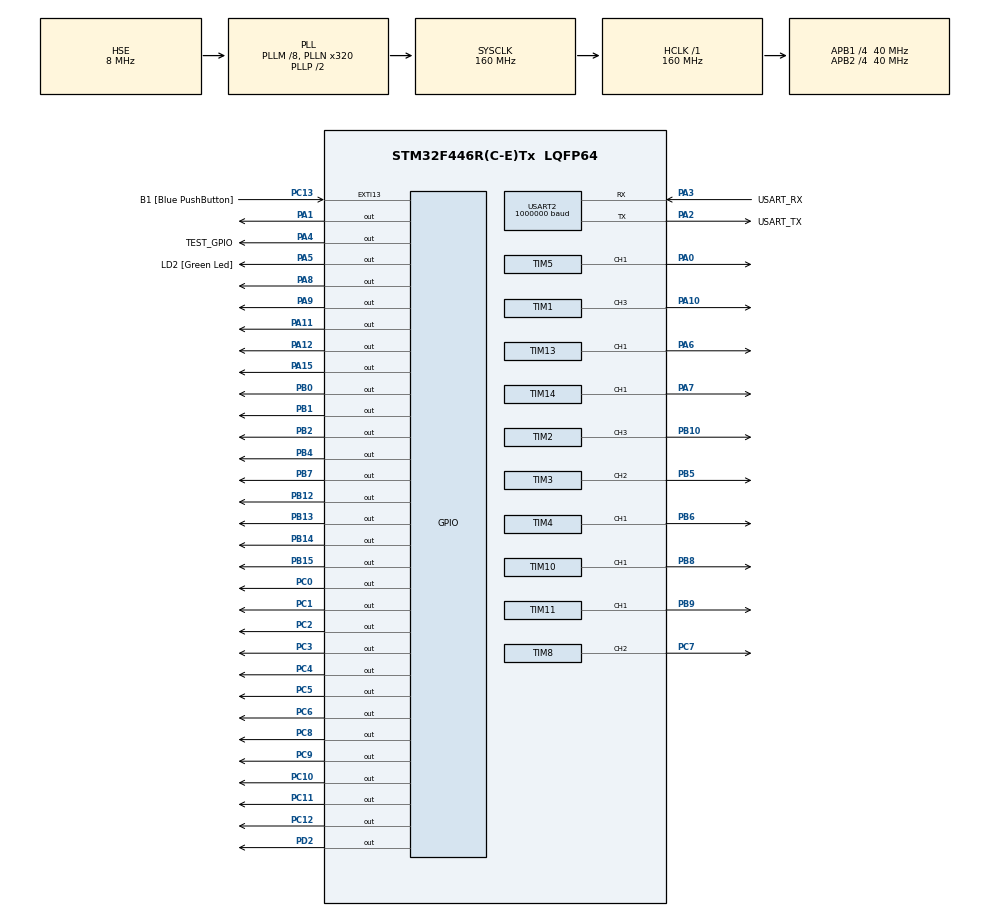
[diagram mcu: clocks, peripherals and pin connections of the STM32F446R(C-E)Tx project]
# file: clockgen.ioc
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Mcu.Family=STM32F4
Mcu.Name=STM32F446R(C-E)Tx
Mcu.Package=LQFP64
Mcu.UserConstants=TIM_TICK_FREQ,1000000;TIM_CLOCK_FREQ,80000000;SYS_CLOCK_FREQ,160000000
NVIC.PriorityGroup=NVIC_PRIORITYGROUP_2
NVIC.TIM6_DAC_IRQn=true\:0\:0\:true\:true\:true\:2\:true\:false
NVIC.USART2_IRQn=true\:0\:0\:true\:true\:true\:1\:true\:false
PA0-WKUP.GPIO_Speed=GPIO_SPEED_FREQ_VERY_HIGH
PA0-WKUP.Signal=S_TIM5_CH1
PA1.GPIO_Speed=GPIO_SPEED_FREQ_VERY_HIGH
PA1.Signal=GPIO_Output
PA10.GPIO_Speed=GPIO_SPEED_FREQ_VERY_HIGH
PA10.Signal=S_TIM1_CH3
PA11.GPIO_Speed=GPIO_SPEED_FREQ_VERY_HIGH
PA11.Signal=GPIO_Output
PA12.GPIO_Speed=GPIO_SPEED_FREQ_VERY_HIGH
PA12.Signal=GPIO_Output
PA13.GPIO_Label=TMS
PA13.Mode=Serial_Wire
PA13.Signal=SYS_JTMS-SWDIO
PA14.GPIO_Label=TCK
PA14.Mode=Serial_Wire
PA14.Signal=SYS_JTCK-SWCLK
PA15.GPIO_Speed=GPIO_SPEED_FREQ_VERY_HIGH
PA15.Signal=GPIO_Output
PA2.GPIO_Label=USART_TX
PA2.Mode=Asynchronous
PA2.Signal=USART2_TX
PA3.GPIO_Label=USART_RX
PA3.Mode=Asynchronous
PA3.Signal=USART2_RX
PA4.GPIO_Label=TEST_GPIO
PA4.GPIO_Speed=GPIO_SPEED_FREQ_VERY_HIGH
PA4.Signal=GPIO_Output
PA5.GPIO_Label=LD2 [Green Led]
PA5.Signal=GPIO_Output
PA6.GPIO_Speed=GPIO_SPEED_FREQ_VERY_HIGH
PA6.Signal=S_TIM13_CH1
PA7.GPIO_Speed=GPIO_SPEED_FREQ_VERY_HIGH
PA7.Signal=S_TIM14_CH1
PA8.GPIO_Speed=GPIO_SPEED_FREQ_VERY_HIGH
PA8.Signal=GPIO_Output
PA9.GPIO_Speed=GPIO_SPEED_FREQ_VERY_HIGH
PA9.Signal=GPIO_Output
PB0.GPIO_Speed=GPIO_SPEED_FREQ_VERY_HIGH
PB0.Signal=GPIO_Output
PB1.GPIO_Speed=GPIO_SPEED_FREQ_VERY_HIGH
PB1.Signal=GPIO_Output
PB10.GPIO_Speed=GPIO_SPEED_FREQ_VERY_HIGH
PB10.Signal=S_TIM2_CH3
PB12.GPIO_Speed=GPIO_SPEED_FREQ_VERY_HIGH
PB12.Signal=GPIO_Output
PB13.GPIO_Speed=GPIO_SPEED_FREQ_VERY_HIGH
PB13.Signal=GPIO_Output
PB14.GPIO_Speed=GPIO_SPEED_FREQ_VERY_HIGH
PB14.Signal=GPIO_Output
PB15.GPIO_Speed=GPIO_SPEED_FREQ_VERY_HIGH
PB15.Signal=GPIO_Output
PB2.GPIO_Speed=GPIO_SPEED_FREQ_VERY_HIGH
PB2.Signal=GPIO_Output
PB3.GPIO_Label=SWO
PB3.Signal=SYS_JTDO-SWO
PB4.GPIO_Speed=GPIO_SPEED_FREQ_VERY_HIGH
PB4.Signal=GPIO_Output
PB5.GPIO_Speed=GPIO_SPEED_FREQ_VERY_HIGH
PB5.Signal=S_TIM3_CH2
PB6.GPIO_Speed=GPIO_SPEED_FREQ_VERY_HIGH
PB6.Signal=S_TIM4_CH1
PB7.GPIO_Speed=GPIO_SPEED_FREQ_VERY_HIGH
PB7.Signal=GPIO_Output
PB8.GPIO_Speed=GPIO_SPEED_FREQ_VERY_HIGH
PB8.Signal=S_TIM10_CH1
PB9.GPIO_Speed=GPIO_SPEED_FREQ_VERY_HIGH
PB9.Signal=S_TIM11_CH1
PC0.GPIO_ModeDefaultOutputPP=GPIO_MODE_OUTPUT_PP
PC0.GPIO_PuPd=GPIO_NOPULL
PC0.GPIO_Speed=GPIO_SPEED_FREQ_VERY_HIGH
PC0.Signal=GPIO_Output
PC1.GPIO_ModeDefaultOutputPP=GPIO_MODE_OUTPUT_PP
PC1.GPIO_PuPd=GPIO_NOPULL
PC1.GPIO_Speed=GPIO_SPEED_FREQ_VERY_HIGH
PC1.Signal=GPIO_Output
PC10.GPIO_Speed=GPIO_SPEED_FREQ_VERY_HIGH
PC10.Signal=GPIO_Output
PC11.GPIO_Speed=GPIO_SPEED_FREQ_VERY_HIGH
PC11.Signal=GPIO_Output
PC12.GPIO_Speed=GPIO_SPEED_FREQ_VERY_HIGH
PC12.Signal=GPIO_Output
PC13.GPIO_Label=B1 [Blue PushButton]
PC13.GPIO_ModeDefaultEXTI=GPIO_MODE_IT_FALLING
PC13.Signal=GPXTI13
PC14-OSC32_IN.Mode=LSE-External-Oscillator
PC14-OSC32_IN.Signal=RCC_OSC32_IN
PC15-OSC32_OUT.Mode=LSE-External-Oscillator
PC15-OSC32_OUT.Signal=RCC_OSC32_OUT
PC2.GPIO_ModeDefaultOutputPP=GPIO_MODE_OUTPUT_PP
PC2.GPIO_PuPd=GPIO_NOPULL
PC2.GPIO_Speed=GPIO_SPEED_FREQ_VERY_HIGH
PC2.Signal=GPIO_Output
PC3.GPIO_ModeDefaultOutputPP=GPIO_MODE_OUTPUT_PP
PC3.GPIO_PuPd=GPIO_NOPULL
PC3.GPIO_Speed=GPIO_SPEED_FREQ_VERY_HIGH
PC3.Signal=GPIO_Output
PC4.GPIO_Speed=GPIO_SPEED_FREQ_VERY_HIGH
PC4.Signal=GPIO_Output
PC5.GPIO_Speed=GPIO_SPEED_FREQ_VERY_HIGH
PC5.Signal=GPIO_Output
PC6.GPIO_Speed=GPIO_SPEED_FREQ_VERY_HIGH
PC6.Signal=GPIO_Output
PC7.GPIO_Speed=GPIO_SPEED_FREQ_VERY_HIGH
PC7.Signal=S_TIM8_CH2
PC8.GPIO_Speed=GPIO_SPEED_FREQ_VERY_HIGH
PC8.Signal=GPIO_Output
PC9.GPIO_Speed=GPIO_SPEED_FREQ_VERY_HIGH
PC9.Signal=GPIO_Output
PD2.GPIO_Speed=GPIO_SPEED_FREQ_VERY_HIGH
PD2.Signal=GPIO_Output
PH0-OSC_IN.Mode=HSE-External-Oscillator
PH0-OSC_IN.Signal=RCC_OSC_IN
PH1-OSC_OUT.Mode=HSE-External-Oscillator
PH1-OSC_OUT.Signal=RCC_OSC_OUT
ProjectManager.HeapSize=0x200
ProjectManager.StackSize=0x400
ProjectManager.TargetToolchain=STM32CubeIDE
RCC.48MHZClocksFreq_Value=84000000
RCC.AHBFreq_Value=160000000
RCC.APB1CLKDivider=RCC_HCLK_DIV4
RCC.APB1Freq_Value=40000000
RCC.APB1TimFreq_Value=80000000
RCC.APB2CLKDivider=RCC_HCLK_DIV4
RCC.APB2Freq_Value=40000000
RCC.APB2TimFreq_Value=80000000
RCC.CortexFreq_Value=160000000
RCC.FLatency-AdvancedSettings=FLASH_LATENCY_5
RCC.HCLKFreq_Value=160000000
RCC.HSE_VALUE=8000000
RCC.HSI_VALUE=16000000
RCC.PLLM=8
RCC.PLLN=320
RCC.PLLSourceVirtual=RCC_PLLSOURCE_HSE
RCC.SYSCLKFreq_VALUE=160000000
RCC.SYSCLKSource=RCC_SYSCLKSOURCE_PLLCLK
RCC.USBFreq_Value=160000000
RCC.VCOOutputFreq_Value=320000000
SH.S_TIM10_CH1.0=TIM10_CH1,Output Compare1 CH1
SH.S_TIM11_CH1.0=TIM11_CH1,Output Compare1 CH1
SH.S_TIM13_CH1.0=TIM13_CH1,Output Compare1 CH1
SH.S_TIM14_CH1.0=TIM14_CH1,Output Compare1 CH1
SH.S_TIM1_CH3.0=TIM1_CH3,Output Compare3 CH3
SH.S_TIM2_CH3.0=TIM2_CH3,Output Compare3 CH3
SH.S_TIM3_CH2.0=TIM3_CH2,Output Compare2 CH2
SH.S_TIM4_CH1.0=TIM4_CH1,Output Compare1 CH1
SH.S_TIM5_CH1.0=TIM5_CH1,Output Compare1 CH1
SH.S_TIM8_CH2.0=TIM8_CH2,Output Compare2 CH2
TIM1.AutoReloadPreload=TIM_AUTORELOAD_PRELOAD_DISABLE
TIM1.AutomaticOutput=TIM_AUTOMATICOUTPUT_ENABLE
TIM1.BreakState=TIM_BREAK_DISABLE
TIM1.Channel-Output\ Compare3\ CH3=TIM_CHANNEL_3
TIM1.OC3Preload=ENABLE
TIM1.OCIdleState_3=TIM_OCIDLESTATE_RESET
TIM1.OCMode_3=TIM_OCMODE_TOGGLE
TIM1.OCPolarity_3=TIM_OCPOLARITY_LOW
TIM1.OffStateIDLEMode=TIM_OSSI_ENABLE
TIM1.OffStateRunMode=TIM_OSSR_ENABLE
TIM1.Pulse-Output\ Compare3\ CH3=0
TIM1.TIM_MasterOutputTrigger=TIM_TRGO_ENABLE
TIM1.TIM_MasterSlaveMode=TIM_MASTERSLAVEMODE_ENABLE
TIM10.Channel=TIM_CHANNEL_1
TIM10.OCMode_1=TIM_OCMODE_TOGGLE
TIM11.Channel=TIM_CHANNEL_1
TIM11.OCMode_1=TIM_OCMODE_TOGGLE
TIM13.Channel=TIM_CHANNEL_1
TIM13.OCMode_1=TIM_OCMODE_TOGGLE
TIM14.Channel=TIM_CHANNEL_1
TIM14.OCMode_1=TIM_OCMODE_TOGGLE
TIM2.AutoReloadPreload=TIM_AUTORELOAD_PRELOAD_DISABLE
TIM2.Channel-Output\ Compare3\ CH3=TIM_CHANNEL_3
TIM2.OC3Preload=ENABLE
TIM2.OCMode_3=TIM_OCMODE_TOGGLE
TIM2.TIM_MasterOutputTrigger=TIM_TRGO_ENABLE
TIM2.TIM_MasterSlaveMode=TIM_MASTERSLAVEMODE_ENABLE
TIM3.Channel-Output\ Compare2\ CH2=TIM_CHANNEL_2
TIM3.OCMode_2=TIM_OCMODE_TOGGLE
TIM3.Period=6553
TIM4.Channel-Output\ Compare1\ CH1=TIM_CHANNEL_1
TIM4.OCMode_1=TIM_OCMODE_TOGGLE
TIM5.Channel-Output\ Compare1\ CH1=TIM_CHANNEL_1
TIM5.OCMode_1=TIM_OCMODE_TOGGLE
TIM6.Period=(TIM_CLOCK_FREQ/TIM_TICK_FREQ) - 1
TIM8.AutomaticOutput=TIM_AUTOMATICOUTPUT_ENABLE
TIM8.Channel-Output\ Compare2\ CH2=TIM_CHANNEL_2
TIM8.OCMode_2=TIM_OCMODE_TOGGLE
TIM8.OCPolarity_2=TIM_OCPOLARITY_LOW
TIM8.OffStateIDLEMode=TIM_OSSI_ENABLE
TIM8.OffStateRunMode=TIM_OSSR_ENABLE
TIM8.Period=8000
USART2.BaudRate=1000000
USART2.VirtualMode=VM_ASYNC
VP_CRC_VS_CRC.Mode=CRC_Activate
VP_TIM10_VS_ClockSourceINT.Mode=Enable_Timer
VP_TIM11_VS_ClockSourceINT.Mode=Enable_Timer
VP_TIM12_VS_ClockSourceINT.Mode=Internal
VP_TIM13_VS_ClockSourceINT.Mode=Enable_Timer
VP_TIM14_VS_ClockSourceINT.Mode=Enable_Timer
VP_TIM1_VS_ClockSourceINT.Mode=Internal
VP_TIM1_VS_ClockSourceITR.Mode=TriggerSource_ITR0
VP_TIM2_VS_ClockSourceINT.Mode=Internal
VP_TIM2_VS_ClockSourceITR.Mode=TriggerSource_ITR0
VP_TIM2_VS_ControllerModeTrigger.Mode=Trigger Mode
VP_TIM3_VS_ClockSourceINT.Mode=Internal
VP_TIM3_VS_ClockSourceITR.Mode=TriggerSource_ITR0
VP_TIM3_VS_ControllerModeTrigger.Mode=Trigger Mode
VP_TIM4_VS_ClockSourceINT.Mode=Internal
VP_TIM4_VS_ClockSourceITR.Mode=TriggerSource_ITR0
VP_TIM4_VS_ControllerModeTrigger.Mode=Trigger Mode
VP_TIM5_VS_ClockSourceINT.Mode=Internal
VP_TIM5_VS_ClockSourceITR.Mode=TriggerSource_ITR0
VP_TIM5_VS_ControllerModeTrigger.Mode=Trigger Mode
VP_TIM6_VS_ClockSourceINT.Mode=Enable_Timer
VP_TIM8_VS_ClockSourceINT.Mode=Internal
VP_TIM8_VS_ClockSourceITR.Mode=TriggerSource_ITR0
VP_TIM8_VS_ControllerModeTrigger.Mode=Trigger Mode
board=NUCLEO-F446RE

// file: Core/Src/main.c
/* USER CODE BEGIN Header */
/**
 ******************************************************************************
 * @file           : main.c
 * @brief          : Main program body
 ******************************************************************************
 * @attention
 *
 * <h2><center>&copy; Copyright (c) 2021 STMicroelectronics.
 * All rights reserved.</center></h2>
 *
 * This software component is licensed by ST under BSD 3-Clause license,
 * the "License"; You may not use this file except in compliance with the
 * License. You may obtain a copy of the License at:
 *                        opensource.org/licenses/BSD-3-Clause
 *
 ******************************************************************************
 */
/* USER CODE END Header */
#include "main.h"

/* USER CODE BEGIN Includes */
#include "stm32f4xx_hal_def.h"
#include "utils.h"
/* USER CODE END Includes */

CRC_HandleTypeDef hcrc;

TIM_HandleTypeDef htim1;
TIM_HandleTypeDef htim2;
TIM_HandleTypeDef htim3;
TIM_HandleTypeDef htim4;
TIM_HandleTypeDef htim5;
TIM_HandleTypeDef htim6;
TIM_HandleTypeDef htim8;
TIM_HandleTypeDef htim10;
TIM_HandleTypeDef htim11;
TIM_HandleTypeDef htim12;
TIM_HandleTypeDef htim13;
TIM_HandleTypeDef htim14;

UART_HandleTypeDef huart2;

void SystemClock_Config(void);
static void MX_GPIO_Init(void);
static void MX_USART2_UART_Init(void);
static void MX_TIM1_Init(void);
static void MX_TIM2_Init(void);
static void MX_TIM3_Init(void);
static void MX_TIM4_Init(void);
static void MX_TIM5_Init(void);
static void MX_TIM8_Init(void);
static void MX_TIM10_Init(void);
static void MX_TIM11_Init(void);
static void MX_TIM13_Init(void);
static void MX_TIM14_Init(void);
static void MX_TIM6_Init(void);
static void MX_CRC_Init(void);
static void MX_TIM12_Init(void);
static void MX_NVIC_Init(void);

int main(void)
{
  /* USER CODE BEGIN 1 */
	uartrecbufftop = 0;
	progbuftop = 0;
	current_us = 0;
	enum FSM_STATE fsm_state = IDLE;
  /* USER CODE END 1 */

  /* MCU Configuration--------------------------------------------------------*/

  /* Reset of all peripherals, Initializes the Flash interface and the Systick. */
  HAL_Init();

  /* Configure the system clock */
  SystemClock_Config();

  /* Initialize all configured peripherals */
  MX_GPIO_Init();
  MX_USART2_UART_Init();
  MX_TIM1_Init();
  MX_TIM2_Init();
  MX_TIM3_Init();
  MX_TIM4_Init();
  MX_TIM5_Init();
  MX_TIM8_Init();
  MX_TIM10_Init();
  MX_TIM11_Init();
  MX_TIM13_Init();
  MX_TIM14_Init();
  MX_TIM6_Init();
  MX_CRC_Init();
  MX_TIM12_Init();

  /* Initialize interrupts */
  MX_NVIC_Init();
  /* USER CODE BEGIN 2 */
    //enable UART interrupt
	uart_interrupt_toggle(1);
	//disable systick to guarantee execution timings
	SysTick->CTRL = 0;
  /* USER CODE END 2 */

  /* Infinite loop */
  /* USER CODE BEGIN WHILE */
	while (1) {
		fsm();
    /* USER CODE END WHILE */

	}
}

void SystemClock_Config(void)
{
  RCC_OscInitTypeDef RCC_OscInitStruct = {0};
  RCC_ClkInitTypeDef RCC_ClkInitStruct = {0};

  /** Configure the main internal regulator output voltage
  */
  __HAL_RCC_PWR_CLK_ENABLE();
  __HAL_PWR_VOLTAGESCALING_CONFIG(PWR_REGULATOR_VOLTAGE_SCALE1);
  /** Initializes the RCC Oscillators according to the specified parameters
  * in the RCC_OscInitTypeDef structure.
  */
  RCC_OscInitStruct.OscillatorType = RCC_OSCILLATORTYPE_HSE;
  RCC_OscInitStruct.HSEState = RCC_HSE_ON;
  RCC_OscInitStruct.PLL.PLLState = RCC_PLL_ON;
  RCC_OscInitStruct.PLL.PLLSource = RCC_PLLSOURCE_HSE;
  RCC_OscInitStruct.PLL.PLLM = 8;
  RCC_OscInitStruct.PLL.PLLN = 320;
  RCC_OscInitStruct.PLL.PLLP = RCC_PLLP_DIV2;
  RCC_OscInitStruct.PLL.PLLQ = 2;
  RCC_OscInitStruct.PLL.PLLR = 2;
  if (HAL_RCC_OscConfig(&RCC_OscInitStruct) != HAL_OK)
  {
    Error_Handler();
  }
  /** Initializes the CPU, AHB and APB buses clocks
  */
  RCC_ClkInitStruct.ClockType = RCC_CLOCKTYPE_HCLK|RCC_CLOCKTYPE_SYSCLK
                              |RCC_CLOCKTYPE_PCLK1|RCC_CLOCKTYPE_PCLK2;
  RCC_ClkInitStruct.SYSCLKSource = RCC_SYSCLKSOURCE_PLLCLK;
  RCC_ClkInitStruct.AHBCLKDivider = RCC_SYSCLK_DIV1;
  RCC_ClkInitStruct.APB1CLKDivider = RCC_HCLK_DIV4;
  RCC_ClkInitStruct.APB2CLKDivider = RCC_HCLK_DIV4;

  if (HAL_RCC_ClockConfig(&RCC_ClkInitStruct, FLASH_LATENCY_5) != HAL_OK)
  {
    Error_Handler();
  }
}

/**
  * @brief NVIC Configuration.
  * @retval None
  */
static void MX_NVIC_Init(void)
{
  /* USART2_IRQn interrupt configuration */
  HAL_NVIC_SetPriority(USART2_IRQn, 0, 0);
  HAL_NVIC_EnableIRQ(USART2_IRQn);
  /* TIM6_DAC_IRQn interrupt configuration */
  HAL_NVIC_SetPriority(TIM6_DAC_IRQn, 0, 0);
  HAL_NVIC_EnableIRQ(TIM6_DAC_IRQn);
}

static void MX_CRC_Init(void)
{

  hcrc.Instance = CRC;
  if (HAL_CRC_Init(&hcrc) != HAL_OK)
  {
    Error_Handler();
  }

}

static void MX_TIM1_Init(void)
{

  TIM_ClockConfigTypeDef sClockSourceConfig = {0};
  TIM_SlaveConfigTypeDef sSlaveConfig = {0};
  TIM_MasterConfigTypeDef sMasterConfig = {0};
  TIM_OC_InitTypeDef sConfigOC = {0};
  TIM_BreakDeadTimeConfigTypeDef sBreakDeadTimeConfig = {0};

  htim1.Instance = TIM1;
  htim1.Init.Prescaler = 0;
  htim1.Init.CounterMode = TIM_COUNTERMODE_UP;
  htim1.Init.Period = 65535;
  htim1.Init.ClockDivision = TIM_CLOCKDIVISION_DIV1;
  htim1.Init.RepetitionCounter = 0;
  htim1.Init.AutoReloadPreload = TIM_AUTORELOAD_PRELOAD_DISABLE;
  if (HAL_TIM_Base_Init(&htim1) != HAL_OK)
  {
    Error_Handler();
  }
  sClockSourceConfig.ClockSource = TIM_CLOCKSOURCE_INTERNAL;
  if (HAL_TIM_ConfigClockSource(&htim1, &sClockSourceConfig) != HAL_OK)
  {
    Error_Handler();
  }
  if (HAL_TIM_OC_Init(&htim1) != HAL_OK)
  {
    Error_Handler();
  }
  sSlaveConfig.SlaveMode = TIM_SLAVEMODE_DISABLE;
  sSlaveConfig.InputTrigger = TIM_TS_ITR0;
  if (HAL_TIM_SlaveConfigSynchro(&htim1, &sSlaveConfig) != HAL_OK)
  {
    Error_Handler();
  }
  sMasterConfig.MasterOutputTrigger = TIM_TRGO_ENABLE;
  sMasterConfig.MasterSlaveMode = TIM_MASTERSLAVEMODE_ENABLE;
  if (HAL_TIMEx_MasterConfigSynchronization(&htim1, &sMasterConfig) != HAL_OK)
  {
    Error_Handler();
  }
  sConfigOC.OCMode = TIM_OCMODE_TOGGLE;
  sConfigOC.Pulse = 0;
  sConfigOC.OCPolarity = TIM_OCPOLARITY_LOW;
  sConfigOC.OCNPolarity = TIM_OCNPOLARITY_HIGH;
  sConfigOC.OCFastMode = TIM_OCFAST_DISABLE;
  sConfigOC.OCIdleState = TIM_OCIDLESTATE_RESET;
  sConfigOC.OCNIdleState = TIM_OCNIDLESTATE_RESET;
  if (HAL_TIM_OC_ConfigChannel(&htim1, &sConfigOC, TIM_CHANNEL_3) != HAL_OK)
  {
    Error_Handler();
  }
  __HAL_TIM_ENABLE_OCxPRELOAD(&htim1, TIM_CHANNEL_3);
  sBreakDeadTimeConfig.OffStateRunMode = TIM_OSSR_ENABLE;
  sBreakDeadTimeConfig.OffStateIDLEMode = TIM_OSSI_ENABLE;
  sBreakDeadTimeConfig.LockLevel = TIM_LOCKLEVEL_OFF;
  sBreakDeadTimeConfig.DeadTime = 0;
  sBreakDeadTimeConfig.BreakState = TIM_BREAK_DISABLE;
  sBreakDeadTimeConfig.BreakPolarity = TIM_BREAKPOLARITY_HIGH;
  sBreakDeadTimeConfig.AutomaticOutput = TIM_AUTOMATICOUTPUT_ENABLE;
  if (HAL_TIMEx_ConfigBreakDeadTime(&htim1, &sBreakDeadTimeConfig) != HAL_OK)
  {
    Error_Handler();
  }
  HAL_TIM_MspPostInit(&htim1);

}

static void MX_TIM2_Init(void)
{

  TIM_ClockConfigTypeDef sClockSourceConfig = {0};
  TIM_SlaveConfigTypeDef sSlaveConfig = {0};
  TIM_MasterConfigTypeDef sMasterConfig = {0};
  TIM_OC_InitTypeDef sConfigOC = {0};

  htim2.Instance = TIM2;
  htim2.Init.Prescaler = 0;
  htim2.Init.CounterMode = TIM_COUNTERMODE_UP;
  htim2.Init.Period = 4294967295;
  htim2.Init.ClockDivision = TIM_CLOCKDIVISION_DIV1;
  htim2.Init.AutoReloadPreload = TIM_AUTORELOAD_PRELOAD_DISABLE;
  if (HAL_TIM_Base_Init(&htim2) != HAL_OK)
  {
    Error_Handler();
  }
  sClockSourceConfig.ClockSource = TIM_CLOCKSOURCE_INTERNAL;
  if (HAL_TIM_ConfigClockSource(&htim2, &sClockSourceConfig) != HAL_OK)
  {
    Error_Handler();
  }
  if (HAL_TIM_OC_Init(&htim2) != HAL_OK)
  {
    Error_Handler();
  }
  sSlaveConfig.SlaveMode = TIM_SLAVEMODE_TRIGGER;
  sSlaveConfig.InputTrigger = TIM_TS_ITR0;
  if (HAL_TIM_SlaveConfigSynchro(&htim2, &sSlaveConfig) != HAL_OK)
  {
    Error_Handler();
  }
  sMasterConfig.MasterOutputTrigger = TIM_TRGO_ENABLE;
  sMasterConfig.MasterSlaveMode = TIM_MASTERSLAVEMODE_ENABLE;
  if (HAL_TIMEx_MasterConfigSynchronization(&htim2, &sMasterConfig) != HAL_OK)
  {
    Error_Handler();
  }
  sConfigOC.OCMode = TIM_OCMODE_TOGGLE;
  sConfigOC.Pulse = 0;
  sConfigOC.OCPolarity = TIM_OCPOLARITY_HIGH;
  sConfigOC.OCFastMode = TIM_OCFAST_DISABLE;
  if (HAL_TIM_OC_ConfigChannel(&htim2, &sConfigOC, TIM_CHANNEL_3) != HAL_OK)
  {
    Error_Handler();
  }
  __HAL_TIM_ENABLE_OCxPRELOAD(&htim2, TIM_CHANNEL_3);
  HAL_TIM_MspPostInit(&htim2);

}

static void MX_TIM3_Init(void)
{

  TIM_ClockConfigTypeDef sClockSourceConfig = {0};
  TIM_SlaveConfigTypeDef sSlaveConfig = {0};
  TIM_MasterConfigTypeDef sMasterConfig = {0};
  TIM_OC_InitTypeDef sConfigOC = {0};

  htim3.Instance = TIM3;
  htim3.Init.Prescaler = 0;
  htim3.Init.CounterMode = TIM_COUNTERMODE_UP;
  htim3.Init.Period = 6553;
  htim3.Init.ClockDivision = TIM_CLOCKDIVISION_DIV1;
  htim3.Init.AutoReloadPreload = TIM_AUTORELOAD_PRELOAD_DISABLE;
  if (HAL_TIM_Base_Init(&htim3) != HAL_OK)
  {
    Error_Handler();
  }
  sClockSourceConfig.ClockSource = TIM_CLOCKSOURCE_INTERNAL;
  if (HAL_TIM_ConfigClockSource(&htim3, &sClockSourceConfig) != HAL_OK)
  {
    Error_Handler();
  }
  if (HAL_TIM_OC_Init(&htim3) != HAL_OK)
  {
    Error_Handler();
  }
  sSlaveConfig.SlaveMode = TIM_SLAVEMODE_TRIGGER;
  sSlaveConfig.InputTrigger = TIM_TS_ITR0;
  if (HAL_TIM_SlaveConfigSynchro(&htim3, &sSlaveConfig) != HAL_OK)
  {
    Error_Handler();
  }
  sMasterConfig.MasterOutputTrigger = TIM_TRGO_RESET;
  sMasterConfig.MasterSlaveMode = TIM_MASTERSLAVEMODE_DISABLE;
  if (HAL_TIMEx_MasterConfigSynchronization(&htim3, &sMasterConfig) != HAL_OK)
  {
    Error_Handler();
  }
  sConfigOC.OCMode = TIM_OCMODE_TOGGLE;
  sConfigOC.Pulse = 0;
  sConfigOC.OCPolarity = TIM_OCPOLARITY_HIGH;
  sConfigOC.OCFastMode = TIM_OCFAST_DISABLE;
  if (HAL_TIM_OC_ConfigChannel(&htim3, &sConfigOC, TIM_CHANNEL_2) != HAL_OK)
  {
    Error_Handler();
  }
  HAL_TIM_MspPostInit(&htim3);

}

static void MX_TIM4_Init(void)
{

  TIM_ClockConfigTypeDef sClockSourceConfig = {0};
  TIM_SlaveConfigTypeDef sSlaveConfig = {0};
  TIM_MasterConfigTypeDef sMasterConfig = {0};
  TIM_OC_InitTypeDef sConfigOC = {0};

  htim4.Instance = TIM4;
  htim4.Init.Prescaler = 0;
  htim4.Init.CounterMode = TIM_COUNTERMODE_UP;
  htim4.Init.Period = 65535;
  htim4.Init.ClockDivision = TIM_CLOCKDIVISION_DIV1;
  htim4.Init.AutoReloadPreload = TIM_AUTORELOAD_PRELOAD_DISABLE;
  if (HAL_TIM_Base_Init(&htim4) != HAL_OK)
  {
    Error_Handler();
  }
  sClockSourceConfig.ClockSource = TIM_CLOCKSOURCE_INTERNAL;
  if (HAL_TIM_ConfigClockSource(&htim4, &sClockSourceConfig) != HAL_OK)
  {
    Error_Handler();
  }
  if (HAL_TIM_OC_Init(&htim4) != HAL_OK)
  {
    Error_Handler();
  }
  sSlaveConfig.SlaveMode = TIM_SLAVEMODE_TRIGGER;
  sSlaveConfig.InputTrigger = TIM_TS_ITR0;
  if (HAL_TIM_SlaveConfigSynchro(&htim4, &sSlaveConfig) != HAL_OK)
  {
    Error_Handler();
  }
  sMasterConfig.MasterOutputTrigger = TIM_TRGO_RESET;
  sMasterConfig.MasterSlaveMode = TIM_MASTERSLAVEMODE_DISABLE;
  if (HAL_TIMEx_MasterConfigSynchronization(&htim4, &sMasterConfig) != HAL_OK)
  {
    Error_Handler();
  }
  sConfigOC.OCMode = TIM_OCMODE_TOGGLE;
  sConfigOC.Pulse = 0;
  sConfigOC.OCPolarity = TIM_OCPOLARITY_HIGH;
  sConfigOC.OCFastMode = TIM_OCFAST_DISABLE;
  if (HAL_TIM_OC_ConfigChannel(&htim4, &sConfigOC, TIM_CHANNEL_1) != HAL_OK)
  {
    Error_Handler();
  }
  HAL_TIM_MspPostInit(&htim4);

}

static void MX_TIM5_Init(void)
{

  TIM_ClockConfigTypeDef sClockSourceConfig = {0};
  TIM_SlaveConfigTypeDef sSlaveConfig = {0};
  TIM_MasterConfigTypeDef sMasterConfig = {0};
  TIM_OC_InitTypeDef sConfigOC = {0};

  htim5.Instance = TIM5;
  htim5.Init.Prescaler = 0;
  htim5.Init.CounterMode = TIM_COUNTERMODE_UP;
  htim5.Init.Period = 4294967295;
  htim5.Init.ClockDivision = TIM_CLOCKDIVISION_DIV1;
  htim5.Init.AutoReloadPreload = TIM_AUTORELOAD_PRELOAD_DISABLE;
  if (HAL_TIM_Base_Init(&htim5) != HAL_OK)
  {
    Error_Handler();
  }
  sClockSourceConfig.ClockSource = TIM_CLOCKSOURCE_INTERNAL;
  if (HAL_TIM_ConfigClockSource(&htim5, &sClockSourceConfig) != HAL_OK)
  {
    Error_Handler();
  }
  if (HAL_TIM_OC_Init(&htim5) != HAL_OK)
  {
    Error_Handler();
  }
  sSlaveConfig.SlaveMode = TIM_SLAVEMODE_TRIGGER;
  sSlaveConfig.InputTrigger = TIM_TS_ITR0;
  if (HAL_TIM_SlaveConfigSynchro(&htim5, &sSlaveConfig) != HAL_OK)
  {
    Error_Handler();
  }
  sMasterConfig.MasterOutputTrigger = TIM_TRGO_RESET;
  sMasterConfig.MasterSlaveMode = TIM_MASTERSLAVEMODE_DISABLE;
  if (HAL_TIMEx_MasterConfigSynchronization(&htim5, &sMasterConfig) != HAL_OK)
  {
    Error_Handler();
  }
  sConfigOC.OCMode = TIM_OCMODE_TOGGLE;
  sConfigOC.Pulse = 0;
  sConfigOC.OCPolarity = TIM_OCPOLARITY_HIGH;
  sConfigOC.OCFastMode = TIM_OCFAST_DISABLE;
  if (HAL_TIM_OC_ConfigChannel(&htim5, &sConfigOC, TIM_CHANNEL_1) != HAL_OK)
  {
    Error_Handler();
  }
  HAL_TIM_MspPostInit(&htim5);

}

static void MX_TIM6_Init(void)
{

  TIM_MasterConfigTypeDef sMasterConfig = {0};

  htim6.Instance = TIM6;
  htim6.Init.Prescaler = 0;
  htim6.Init.CounterMode = TIM_COUNTERMODE_UP;
  htim6.Init.Period = (TIM_CLOCK_FREQ/TIM_TICK_FREQ) - 1;
  htim6.Init.AutoReloadPreload = TIM_AUTORELOAD_PRELOAD_DISABLE;
  if (HAL_TIM_Base_Init(&htim6) != HAL_OK)
  {
    Error_Handler();
  }
  sMasterConfig.MasterOutputTrigger = TIM_TRGO_RESET;
  sMasterConfig.MasterSlaveMode = TIM_MASTERSLAVEMODE_DISABLE;
  if (HAL_TIMEx_MasterConfigSynchronization(&htim6, &sMasterConfig) != HAL_OK)
  {
    Error_Handler();
  }

}

static void MX_TIM8_Init(void)
{

  TIM_ClockConfigTypeDef sClockSourceConfig = {0};
  TIM_SlaveConfigTypeDef sSlaveConfig = {0};
  TIM_MasterConfigTypeDef sMasterConfig = {0};
  TIM_OC_InitTypeDef sConfigOC = {0};
  TIM_BreakDeadTimeConfigTypeDef sBreakDeadTimeConfig = {0};

  htim8.Instance = TIM8;
  htim8.Init.Prescaler = 0;
  htim8.Init.CounterMode = TIM_COUNTERMODE_UP;
  htim8.Init.Period = 8000;
  htim8.Init.ClockDivision = TIM_CLOCKDIVISION_DIV1;
  htim8.Init.RepetitionCounter = 0;
  htim8.Init.AutoReloadPreload = TIM_AUTORELOAD_PRELOAD_DISABLE;
  if (HAL_TIM_Base_Init(&htim8) != HAL_OK)
  {
    Error_Handler();
  }
  sClockSourceConfig.ClockSource = TIM_CLOCKSOURCE_INTERNAL;
  if (HAL_TIM_ConfigClockSource(&htim8, &sClockSourceConfig) != HAL_OK)
  {
    Error_Handler();
  }
  if (HAL_TIM_OC_Init(&htim8) != HAL_OK)
  {
    Error_Handler();
  }
  sSlaveConfig.SlaveMode = TIM_SLAVEMODE_TRIGGER;
  sSlaveConfig.InputTrigger = TIM_TS_ITR0;
  if (HAL_TIM_SlaveConfigSynchro(&htim8, &sSlaveConfig) != HAL_OK)
  {
    Error_Handler();
  }
  sMasterConfig.MasterOutputTrigger = TIM_TRGO_RESET;
  sMasterConfig.MasterSlaveMode = TIM_MASTERSLAVEMODE_DISABLE;
  if (HAL_TIMEx_MasterConfigSynchronization(&htim8, &sMasterConfig) != HAL_OK)
  {
    Error_Handler();
  }
  sConfigOC.OCMode = TIM_OCMODE_TOGGLE;
  sConfigOC.Pulse = 0;
  sConfigOC.OCPolarity = TIM_OCPOLARITY_LOW;
  sConfigOC.OCNPolarity = TIM_OCNPOLARITY_HIGH;
  sConfigOC.OCFastMode = TIM_OCFAST_DISABLE;
  sConfigOC.OCIdleState = TIM_OCIDLESTATE_RESET;
  sConfigOC.OCNIdleState = TIM_OCNIDLESTATE_RESET;
  if (HAL_TIM_OC_ConfigChannel(&htim8, &sConfigOC, TIM_CHANNEL_2) != HAL_OK)
  {
    Error_Handler();
  }
  sBreakDeadTimeConfig.OffStateRunMode = TIM_OSSR_ENABLE;
  sBreakDeadTimeConfig.OffStateIDLEMode = TIM_OSSI_ENABLE;
  sBreakDeadTimeConfig.LockLevel = TIM_LOCKLEVEL_OFF;
  sBreakDeadTimeConfig.DeadTime = 0;
  sBreakDeadTimeConfig.BreakState = TIM_BREAK_DISABLE;
  sBreakDeadTimeConfig.BreakPolarity = TIM_BREAKPOLARITY_HIGH;
  sBreakDeadTimeConfig.AutomaticOutput = TIM_AUTOMATICOUTPUT_ENABLE;
  if (HAL_TIMEx_ConfigBreakDeadTime(&htim8, &sBreakDeadTimeConfig) != HAL_OK)
  {
    Error_Handler();
  }
  HAL_TIM_MspPostInit(&htim8);

}

static void MX_TIM10_Init(void)
{

  TIM_OC_InitTypeDef sConfigOC = {0};

  htim10.Instance = TIM10;
  htim10.Init.Prescaler = 0;
  htim10.Init.CounterMode = TIM_COUNTERMODE_UP;
  htim10.Init.Period = 65535;
  htim10.Init.ClockDivision = TIM_CLOCKDIVISION_DIV1;
  htim10.Init.AutoReloadPreload = TIM_AUTORELOAD_PRELOAD_DISABLE;
  if (HAL_TIM_Base_Init(&htim10) != HAL_OK)
  {
    Error_Handler();
  }
  if (HAL_TIM_OC_Init(&htim10) != HAL_OK)
  {
    Error_Handler();
  }
  sConfigOC.OCMode = TIM_OCMODE_TOGGLE;
  sConfigOC.Pulse = 0;
  sConfigOC.OCPolarity = TIM_OCPOLARITY_HIGH;
  sConfigOC.OCFastMode = TIM_OCFAST_DISABLE;
  if (HAL_TIM_OC_ConfigChannel(&htim10, &sConfigOC, TIM_CHANNEL_1) != HAL_OK)
  {
    Error_Handler();
  }
  HAL_TIM_MspPostInit(&htim10);

}

static void MX_TIM11_Init(void)
{

  TIM_OC_InitTypeDef sConfigOC = {0};

  htim11.Instance = TIM11;
  htim11.Init.Prescaler = 0;
  htim11.Init.CounterMode = TIM_COUNTERMODE_UP;
  htim11.Init.Period = 65535;
  htim11.Init.ClockDivision = TIM_CLOCKDIVISION_DIV1;
  htim11.Init.AutoReloadPreload = TIM_AUTORELOAD_PRELOAD_DISABLE;
  if (HAL_TIM_Base_Init(&htim11) != HAL_OK)
  {
    Error_Handler();
  }
  if (HAL_TIM_OC_Init(&htim11) != HAL_OK)
  {
    Error_Handler();
  }
  sConfigOC.OCMode = TIM_OCMODE_TOGGLE;
  sConfigOC.Pulse = 0;
  sConfigOC.OCPolarity = TIM_OCPOLARITY_HIGH;
  sConfigOC.OCFastMode = TIM_OCFAST_DISABLE;
  if (HAL_TIM_OC_ConfigChannel(&htim11, &sConfigOC, TIM_CHANNEL_1) != HAL_OK)
  {
    Error_Handler();
  }
  HAL_TIM_MspPostInit(&htim11);

}

static void MX_TIM12_Init(void)
{

  TIM_ClockConfigTypeDef sClockSourceConfig = {0};

  htim12.Instance = TIM12;
  htim12.Init.Prescaler = 0;
  htim12.Init.CounterMode = TIM_COUNTERMODE_UP;
  htim12.Init.Period = 65535;
  htim12.Init.ClockDivision = TIM_CLOCKDIVISION_DIV1;
  htim12.Init.AutoReloadPreload = TIM_AUTORELOAD_PRELOAD_DISABLE;
  if (HAL_TIM_Base_Init(&htim12) != HAL_OK)
  {
    Error_Handler();
  }
  sClockSourceConfig.ClockSource = TIM_CLOCKSOURCE_INTERNAL;
  if (HAL_TIM_ConfigClockSource(&htim12, &sClockSourceConfig) != HAL_OK)
  {
    Error_Handler();
  }

}

static void MX_TIM13_Init(void)
{

  TIM_OC_InitTypeDef sConfigOC = {0};

  htim13.Instance = TIM13;
  htim13.Init.Prescaler = 0;
  htim13.Init.CounterMode = TIM_COUNTERMODE_UP;
  htim13.Init.Period = 65535;
  htim13.Init.ClockDivision = TIM_CLOCKDIVISION_DIV1;
  htim13.Init.AutoReloadPreload = TIM_AUTORELOAD_PRELOAD_DISABLE;
  if (HAL_TIM_Base_Init(&htim13) != HAL_OK)
  {
    Error_Handler();
  }
  if (HAL_TIM_OC_Init(&htim13) != HAL_OK)
  {
    Error_Handler();
  }
  sConfigOC.OCMode = TIM_OCMODE_TOGGLE;
  sConfigOC.Pulse = 0;
  sConfigOC.OCPolarity = TIM_OCPOLARITY_HIGH;
  sConfigOC.OCFastMode = TIM_OCFAST_DISABLE;
  if (HAL_TIM_OC_ConfigChannel(&htim13, &sConfigOC, TIM_CHANNEL_1) != HAL_OK)
  {
    Error_Handler();
  }
  HAL_TIM_MspPostInit(&htim13);

}

static void MX_TIM14_Init(void)
{

  TIM_OC_InitTypeDef sConfigOC = {0};

  htim14.Instance = TIM14;
  htim14.Init.Prescaler = 0;
  htim14.Init.CounterMode = TIM_COUNTERMODE_UP;
  htim14.Init.Period = 65535;
  htim14.Init.ClockDivision = TIM_CLOCKDIVISION_DIV1;
  htim14.Init.AutoReloadPreload = TIM_AUTORELOAD_PRELOAD_DISABLE;
  if (HAL_TIM_Base_Init(&htim14) != HAL_OK)
  {
    Error_Handler();
  }
  if (HAL_TIM_OC_Init(&htim14) != HAL_OK)
  {
    Error_Handler();
  }
  sConfigOC.OCMode = TIM_OCMODE_TOGGLE;
  sConfigOC.Pulse = 0;
  sConfigOC.OCPolarity = TIM_OCPOLARITY_HIGH;
  sConfigOC.OCFastMode = TIM_OCFAST_DISABLE;
  if (HAL_TIM_OC_ConfigChannel(&htim14, &sConfigOC, TIM_CHANNEL_1) != HAL_OK)
  {
    Error_Handler();
  }
  HAL_TIM_MspPostInit(&htim14);

}

static void MX_USART2_UART_Init(void)
{

  huart2.Instance = USART2;
  huart2.Init.BaudRate = 1000000;
  huart2.Init.WordLength = UART_WORDLENGTH_8B;
  huart2.Init.StopBits = UART_STOPBITS_1;
  huart2.Init.Parity = UART_PARITY_NONE;
  huart2.Init.Mode = UART_MODE_TX_RX;
  huart2.Init.HwFlowCtl = UART_HWCONTROL_NONE;
  huart2.Init.OverSampling = UART_OVERSAMPLING_16;
  if (HAL_UART_Init(&huart2) != HAL_OK)
  {
    Error_Handler();
  }

}

static void MX_GPIO_Init(void)
{
  GPIO_InitTypeDef GPIO_InitStruct = {0};

  /* GPIO Ports Clock Enable */
  __HAL_RCC_GPIOC_CLK_ENABLE();
  __HAL_RCC_GPIOH_CLK_ENABLE();
  __HAL_RCC_GPIOA_CLK_ENABLE();
  __HAL_RCC_GPIOB_CLK_ENABLE();
  __HAL_RCC_GPIOD_CLK_ENABLE();

  /*Configure GPIO pin Output Level */
  HAL_GPIO_WritePin(GPIOC, GPIO_PIN_0|GPIO_PIN_1|GPIO_PIN_2|GPIO_PIN_3
                          |GPIO_PIN_4|GPIO_PIN_5|GPIO_PIN_6|GPIO_PIN_8
                          |GPIO_PIN_9|GPIO_PIN_10|GPIO_PIN_11|GPIO_PIN_12, GPIO_PIN_RESET);

  /*Configure GPIO pin Output Level */
  HAL_GPIO_WritePin(GPIOA, GPIO_PIN_1|TEST_GPIO_Pin|LD2_Pin|GPIO_PIN_8
                          |GPIO_PIN_9|GPIO_PIN_11|GPIO_PIN_12|GPIO_PIN_15, GPIO_PIN_RESET);

  /*Configure GPIO pin Output Level */
  HAL_GPIO_WritePin(GPIOB, GPIO_PIN_0|GPIO_PIN_1|GPIO_PIN_2|GPIO_PIN_12
                          |GPIO_PIN_13|GPIO_PIN_14|GPIO_PIN_15|GPIO_PIN_4
                          |GPIO_PIN_7, GPIO_PIN_RESET);

  /*Configure GPIO pin Output Level */
  HAL_GPIO_WritePin(GPIOD, GPIO_PIN_2, GPIO_PIN_RESET);

  /*Configure GPIO pin : B1_Pin */
  GPIO_InitStruct.Pin = B1_Pin;
  GPIO_InitStruct.Mode = GPIO_MODE_IT_FALLING;
  GPIO_InitStruct.Pull = GPIO_NOPULL;
  HAL_GPIO_Init(B1_GPIO_Port, &GPIO_InitStruct);

  /*Configure GPIO pins : PC0 PC1 PC2 PC3
                           PC4 PC5 PC6 PC8
                           PC9 PC10 PC11 PC12 */
  GPIO_InitStruct.Pin = GPIO_PIN_0|GPIO_PIN_1|GPIO_PIN_2|GPIO_PIN_3
                          |GPIO_PIN_4|GPIO_PIN_5|GPIO_PIN_6|GPIO_PIN_8
                          |GPIO_PIN_9|GPIO_PIN_10|GPIO_PIN_11|GPIO_PIN_12;
  GPIO_InitStruct.Mode = GPIO_MODE_OUTPUT_PP;
  GPIO_InitStruct.Pull = GPIO_NOPULL;
  GPIO_InitStruct.Speed = GPIO_SPEED_FREQ_VERY_HIGH;
  HAL_GPIO_Init(GPIOC, &GPIO_InitStruct);

  /*Configure GPIO pins : PA1 TEST_GPIO_Pin PA8 PA9
                           PA11 PA12 PA15 */
  GPIO_InitStruct.Pin = GPIO_PIN_1|TEST_GPIO_Pin|GPIO_PIN_8|GPIO_PIN_9
                          |GPIO_PIN_11|GPIO_PIN_12|GPIO_PIN_15;
  GPIO_InitStruct.Mode = GPIO_MODE_OUTPUT_PP;
  GPIO_InitStruct.Pull = GPIO_NOPULL;
  GPIO_InitStruct.Speed = GPIO_SPEED_FREQ_VERY_HIGH;
  HAL_GPIO_Init(GPIOA, &GPIO_InitStruct);

  /*Configure GPIO pin : LD2_Pin */
  GPIO_InitStruct.Pin = LD2_Pin;
  GPIO_InitStruct.Mode = GPIO_MODE_OUTPUT_PP;
  GPIO_InitStruct.Pull = GPIO_NOPULL;
  GPIO_InitStruct.Speed = GPIO_SPEED_FREQ_LOW;
  HAL_GPIO_Init(LD2_GPIO_Port, &GPIO_InitStruct);

  /*Configure GPIO pins : PB0 PB1 PB2 PB12
                           PB13 PB14 PB15 PB4
                           PB7 */
  GPIO_InitStruct.Pin = GPIO_PIN_0|GPIO_PIN_1|GPIO_PIN_2|GPIO_PIN_12
                          |GPIO_PIN_13|GPIO_PIN_14|GPIO_PIN_15|GPIO_PIN_4
                          |GPIO_PIN_7;
  GPIO_InitStruct.Mode = GPIO_MODE_OUTPUT_PP;
  GPIO_InitStruct.Pull = GPIO_NOPULL;
  GPIO_InitStruct.Speed = GPIO_SPEED_FREQ_VERY_HIGH;
  HAL_GPIO_Init(GPIOB, &GPIO_InitStruct);

  /*Configure GPIO pin : PD2 */
  GPIO_InitStruct.Pin = GPIO_PIN_2;
  GPIO_InitStruct.Mode = GPIO_MODE_OUTPUT_PP;
  GPIO_InitStruct.Pull = GPIO_NOPULL;
  GPIO_InitStruct.Speed = GPIO_SPEED_FREQ_VERY_HIGH;
  HAL_GPIO_Init(GPIOD, &GPIO_InitStruct);

}

void Error_Handler(void)
{
	__disable_irq();
	while (1) {
	}
}

/************************ (C) COPYRIGHT STMicroelectronics *****END OF FILE****/
